CM_ "IMPORT _subaru_preglobal_2015.dbc";

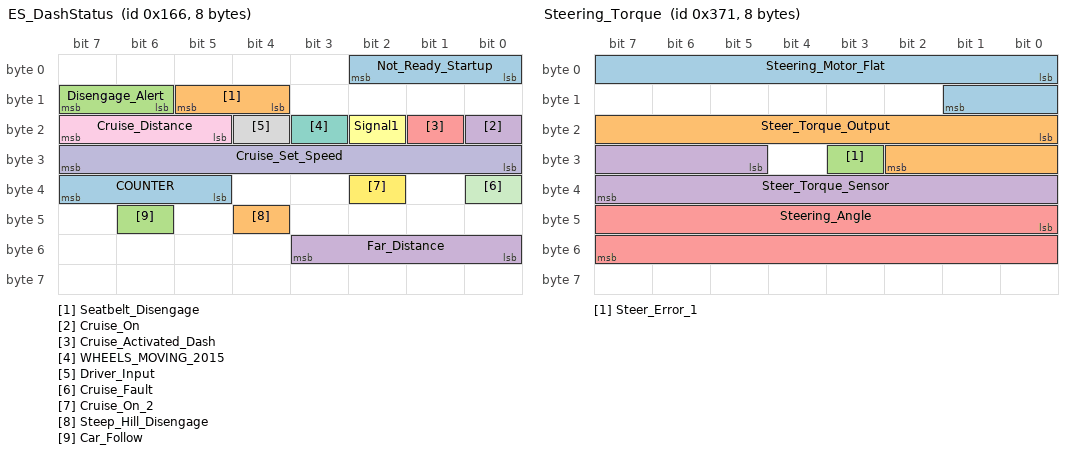
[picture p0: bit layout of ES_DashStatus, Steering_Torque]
BO_ 358 ES_DashStatus: 8 XXX
 SG_ Not_Ready_Startup : 0|3@1+ (1,0) [0|7] "" XXX
 SG_ Seatbelt_Disengage : 12|2@1+ (1,0) [0|3] "" XXX
 SG_ Disengage_Alert : 14|2@1+ (1,0) [0|3] "" XXX
 SG_ Cruise_On : 16|1@1+ (1,0) [0|1] "" XXX
 SG_ Cruise_Activated_Dash : 17|1@1+ (1,0) [0|1] "" XXX
 SG_ Signal1 : 18|1@1+ (1,0) [0|1] "" XXX
 SG_ WHEELS_MOVING_2015 : 19|1@1+ (1,0) [0|1] "" XXX
 SG_ Driver_Input : 20|1@1+ (1,0) [0|1] "" XXX
 SG_ Cruise_Distance : 21|3@1+ (1,0) [0|7] "" XXX
 SG_ Cruise_Set_Speed : 24|8@1+ (1,0) [0|255] "" XXX
 SG_ Cruise_Fault : 32|1@1+ (1,0) [0|1] "" XXX
 SG_ Cruise_On_2 : 34|1@1+ (1,0) [0|1] "" XXX
 SG_ COUNTER : 37|3@1+ (1,0) [0|7] "" XXX
 SG_ Steep_Hill_Disengage : 44|1@1+ (1,0) [0|3] "" XXX
 SG_ Car_Follow : 46|1@1+ (1,0) [0|1] "" XXX
 SG_ Far_Distance : 48|4@1+ (5,0) [0|75] "m" XXX

BO_ 881 Steering_Torque: 8 XXX
 SG_ Steering_Motor_Flat : 0|10@1+ (32,0) [0|1000] "" XXX
 SG_ Steer_Torque_Output : 16|11@1- (-32,0) [-1000|1000] "" XXX
 SG_ Steer_Error_1 : 27|1@1+ (1,0) [0|1] "" XXX
 SG_ Steer_Torque_Sensor : 29|11@1- (-1,0) [-1000|1000] "" XXX
 SG_ Steering_Angle : 40|16@1- (-0.033,0) [-600|600] "" XXX

CM_ SG_ 358 Disengage_Alert "seatbelt and steep hill disengage";
CM_ SG_ 358 Cruise_Fault "No engagement until restart";
CM_ SG_ 358 Car_Follow "lead car detected";
